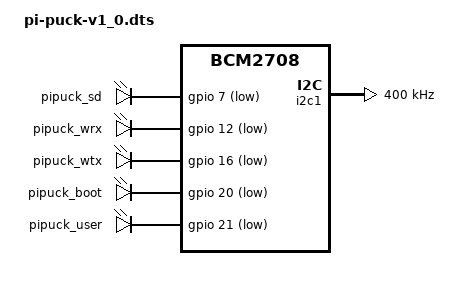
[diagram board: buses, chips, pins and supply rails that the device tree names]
/dts-v1/;
/plugin/;

/ {
	compatible = "brcm,bcm2708";

	/* LEDs */
	fragment@0 {
		target = <&leds>;
		__overlay__ {
			compatible = "gpio-leds";
			pipuck_sd {
				label = "pipuck_sd";
				gpios = <&gpio 7 1>; // LED1
				linux,default-trigger = "mmc0";
			};
			pipuck_wrx {
				label = "pipuck_wrx";
				gpios = <&gpio 12 1>; // LED2
				linux,default-trigger = "phy0rx";
			};
			pipuck_wtx {
				label = "pipuck_wtx";
				gpios = <&gpio 16 1>; // LED3
				linux,default-trigger = "phy0tx";
			};
			pipuck_boot {
				label = "pipuck_boot";
				gpios = <&gpio 20 1>; // LED4
				linux,default-trigger = "heartbeat";
			};
			pipuck_user {
				label = "pipuck_user";
				gpios = <&gpio 21 1>; // LED5
			};
		};
	};

	/* Control switch keys */
	fragment@1 {
		target-path = "/soc";
		__dormant__ {
			control-switches {
				compatible = "gpio-keys";
				pipuck_switch1 {
					label = "pipuck_switch1";
					gpios = <&gpio 26 0>; // SW1
					linux,code = <256>;
				};
			};
		};
	};
	fragment@2 {
		target-path = "/soc";
		__dormant__ {
			control-switches {
				compatible = "gpio-keys";
				pipuck_switch2 {
					label = "pipuck_switch2";
					gpios = <&gpio 19 0>; // SW2
					linux,code = <257>;
				};
				pipuck_switch3 {
					label = "pipuck_switch3";
					gpios = <&gpio 13 0>; // SW3
					linux,code = <258>;
				};
				pipuck_switch4 {
					label = "pipuck_switch4";
					gpios = <&gpio 17 0>; // SW4
					linux,code = <259>;
				};
			};
		};
	};

	/* Control switch power key */
	fragment@3 {
		target-path = "/soc";
		__dormant__ {
			control-switches {
				compatible = "gpio-keys";
				pipuck_power_key: pipuck_switch1 {
					label = "shutdown";
					linux,code = <116>; // KEY_POWER
					gpios = <&gpio 26 0>;
					debounce-interval = <2000>;
				};

			};
		};
	};

	/* Low battery signal power trigger */
	fragment@4 {
		target-path = "/soc";
		__dormant__ {
			control-switches {
				compatible = "gpio-keys";
				pipuck_batt_low: pipuck_batt_low {
					label = "shutdown";
					linux,code = <116>; // KEY_POWER
					gpios = <&gpio 27 1>;
					debounce-interval = <2000>;
				};

			};
		};
	};

	/* I2C devices */
	fragment@5 {
		target = <&i2c1>;
		__overlay__ {
			#address-cells = <1>;
			#size-cells = <0>;
			status = "okay";
			clock-frequency = <400000>;
			/* e-puck */
		};
	};

	/* Disable Bluetooth to free up UART */
	fragment@6 {
		target = <&uart1>;
		__dormant__ {
			status = "disabled";
		};
	};
	fragment@7 {
		target = <&uart0>;
		__dormant__ {
			pinctrl-names = "default";
			pinctrl-0 = <&uart0_pins>;
			status = "okay";
		};
	};
	fragment@8 {
		target = <&uart0_pins>;
		__dormant__ {
			brcm,pins;
			brcm,function;
			brcm,pull;
		};
	};
	fragment@9 {
		target-path = "/aliases";
		__dormant__ {
			serial0 = "/soc/serial@7e201000";
			serial1 = "/soc/serial@7e215040";
		};
	};

	__overrides__ {
		control_keys = <0>,"+1+2";
		power_key = <0>,"-1+3";
		power_key_debounce = <&pipuck_power_key>,"debounce-interval:0";
		batt_low = <0>,"+4";
		batt_low_debounce = <&pipuck_batt_low>,"debounce-interval:0";
		uart = <0>,"+6+7+8+9";
	};
};
